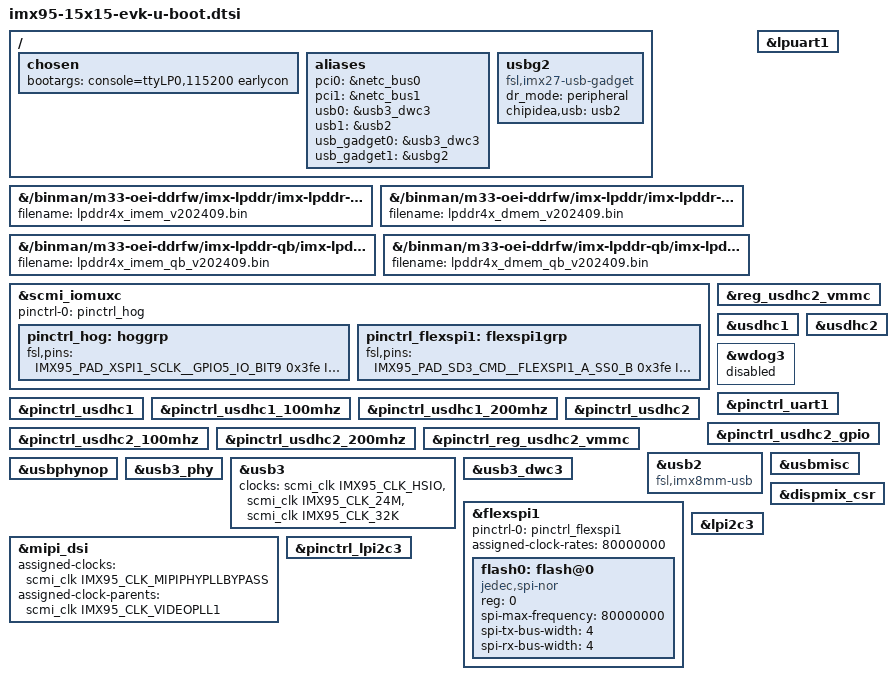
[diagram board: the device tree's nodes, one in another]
// SPDX-License-Identifier: GPL-2.0+
/*
 * Copyright 2025 NXP
 */

#include "imx95-u-boot.dtsi"

/ {
	chosen {
		bootargs = "console=ttyLP0,115200 earlycon";
	};

	aliases {
		pci0 = &netc_bus0;
		pci1 = &netc_bus1;
		usb0 = &usb3_dwc3;
		usb1 = &usb2;
		usb_gadget0 = &usb3_dwc3;
		usb_gadget1 = &usbg2;
	};

	usbg2: usbg2 {
		compatible = "fsl,imx27-usb-gadget";
		dr_mode = "peripheral";
		chipidea,usb = <&usb2>;
		bootph-pre-ram;
		status = "okay";
	};
};

&{/binman/m33-oei-ddrfw/imx-lpddr/imx-lpddr-imem} {
	filename = "lpddr4x_imem_v202409.bin";
};

&{/binman/m33-oei-ddrfw/imx-lpddr/imx-lpddr-dmem} {
	filename = "lpddr4x_dmem_v202409.bin";
};

&{/binman/m33-oei-ddrfw/imx-lpddr-qb/imx-lpddr-imem-qb} {
	filename = "lpddr4x_imem_qb_v202409.bin";
};

&{/binman/m33-oei-ddrfw/imx-lpddr-qb/imx-lpddr-dmem-qb} {
	filename = "lpddr4x_dmem_qb_v202409.bin";
};

&scmi_iomuxc {
	pinctrl-names = "default";
	pinctrl-0 = <&pinctrl_hog>;

	pinctrl_hog: hoggrp {
		bootph-all;
		bootph-pre-ram;

		fsl,pins = <
			IMX95_PAD_XSPI1_SCLK__GPIO5_IO_BIT9			0x3fe
			IMX95_PAD_CCM_CLKO1__GPIO3_IO_BIT26			0x30e
			IMX95_PAD_CCM_CLKO2__GPIO3_IO_BIT27			0x30e
		>;
	};

	pinctrl_flexspi1: flexspi1grp {
		fsl,pins = <
			IMX95_PAD_SD3_CMD__FLEXSPI1_A_SS0_B			0x3fe
			IMX95_PAD_XSPI1_SCLK__GPIO5_IO_BIT9			0x3fe
			IMX95_PAD_SD3_CLK__FLEXSPI1_A_SCLK			0x3fe
			IMX95_PAD_SD3_DATA0__FLEXSPI1_A_DATA_BIT0		0x3fe
			IMX95_PAD_SD3_DATA1__FLEXSPI1_A_DATA_BIT1		0x3fe
			IMX95_PAD_SD3_DATA2__FLEXSPI1_A_DATA_BIT2		0x3fe
			IMX95_PAD_SD3_DATA3__FLEXSPI1_A_DATA_BIT3		0x3fe
		>;
	};
};

&lpuart1 {
	bootph-pre-ram;
};

&reg_usdhc2_vmmc {
	bootph-pre-ram;
};

&usdhc1 {
	bootph-pre-ram;
};

&usdhc2 {
	bootph-pre-ram;
};

&wdog3 {
	status = "disabled";
};

&pinctrl_uart1 {
	bootph-pre-ram;
};

&pinctrl_usdhc1 {
	bootph-pre-ram;
};

&pinctrl_usdhc1_100mhz {
	bootph-pre-ram;
};

&pinctrl_usdhc1_200mhz {
	bootph-pre-ram;
};

&pinctrl_usdhc2 {
	bootph-pre-ram;
};

&pinctrl_usdhc2_100mhz {
	bootph-pre-ram;
};

&pinctrl_usdhc2_200mhz {
	bootph-pre-ram;
};

&pinctrl_usdhc2_gpio {
	bootph-pre-ram;
};

&pinctrl_reg_usdhc2_vmmc {
	bootph-pre-ram;
};

&usb2 {
	compatible = "fsl,imx8mm-usb", "fsl,imx7d-usb";
	/delete-property/power-domains;
	bootph-pre-ram;
};

&usbmisc {
	bootph-pre-ram;
};

&usbphynop {
	bootph-pre-ram;
};

&usb3_phy {
	bootph-pre-ram;
};

&usb3 {
	clocks = <&scmi_clk IMX95_CLK_HSIO>,
			 <&scmi_clk IMX95_CLK_24M>,
			 <&scmi_clk IMX95_CLK_32K>;
	clock-names = "hsio", "ref", "suspend";

	/delete-property/power-domains;
	bootph-pre-ram;
};

&usb3_dwc3 {
	bootph-pre-ram;
};

&flexspi1 {
	pinctrl-names = "default";
	pinctrl-0 = <&pinctrl_flexspi1>;
	assigned-clock-rates = <80000000>;
	status = "okay";

	flash0: flash@0 {
		reg = <0>;
		#address-cells = <1>;
		#size-cells = <1>;
		compatible = "jedec,spi-nor";
		spi-max-frequency = <80000000>;
		spi-tx-bus-width = <4>;
		spi-rx-bus-width = <4>;
	};
};

&dispmix_csr {
	/delete-property/ assigned-clocks;
	/delete-property/ assigned-clock-rates;
	/delete-property/ assigned-clock-parents;
};

&mipi_dsi {
	assigned-clocks = <&scmi_clk IMX95_CLK_MIPIPHYPLLBYPASS>;
	assigned-clock-parents = <&scmi_clk IMX95_CLK_VIDEOPLL1>;
};


&lpi2c3 {
	bootph-some-ram;
};

&pinctrl_lpi2c3 {
	bootph-some-ram;
};
